VERSION ""

NS_ :

BS_:

BU_: INPUTIOA HPPCTX

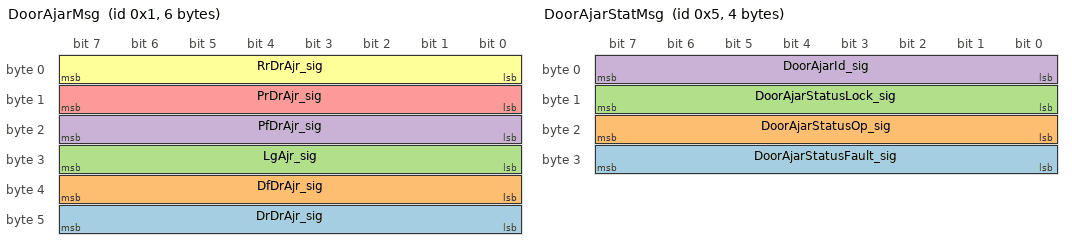
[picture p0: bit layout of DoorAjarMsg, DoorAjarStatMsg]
BO_ 1 DoorAjarMsg: 6 HPPCTX
 SG_ DrDrAjr_sig : 40|8@1+ (1,0) [0|3] "-"  INPUTIOA
 SG_ DfDrAjr_sig : 32|8@1+ (1,0) [0|3] "-"  INPUTIOA
 SG_ LgAjr_sig : 24|8@1+ (1,0) [0|3] "-"  INPUTIOA
 SG_ PfDrAjr_sig : 16|8@1+ (1,0) [0|3] "-"  INPUTIOA
 SG_ PrDrAjr_sig : 8|8@1+ (1,0) [0|3] "-"  INPUTIOA
 SG_ RrDrAjr_sig : 0|8@1+ (1,0) [0|3] "-"  INPUTIOA

BO_ 2 AmbLightMsg: 1 HPPCTX
 SG_ AutLmpSens_sig : 0|8@1+ (1,0) [0|6] "-"  INPUTIOA

BO_ 3 RnLgthMsg: 2 HPPCTX
 SG_ AmbLghtExtLght_sig : 8|8@1+ (1,0) [0|5] "-"  INPUTIOA
 SG_ AmbLghtExtLghtStatCom_sig : 0|8@1+ (1,0) [0|1] "-"  INPUTIOA

BO_ 4 HdLmpSwitchMsg: 1 HPPCTX
 SG_ AbsPos_sig : 0|8@1+ (1,0) [0|5] "-"  INPUTIOA

BO_ 5 DoorAjarStatMsg: 4 INPUTIOA
 SG_ DoorAjarStatusFault_sig : 24|8@1+ (1,0) [0|3] "-"  HPPCTX
 SG_ DoorAjarStatusOp_sig : 16|8@1+ (1,0) [0|3] "-"  HPPCTX
 SG_ DoorAjarStatusLock_sig : 8|8@1+ (1,0) [0|3] "-"  HPPCTX
 SG_ DoorAjarId_sig : 0|8@1+ (1,0) [0|3] "-"  HPPCTX

BO_ 6 AmbLightPDUMsg: 1 INPUTIOA
 SG_ AmbLghtLvlStsPDU_sig : 0|8@1+ (1,0) [0|6] "-"  HPPCTX

BO_ 7 RnLgthPDUMsg: 1 INPUTIOA
 SG_ AmbLghtExtLghtLvl_sig : 0|8@1+ (1,0) [0|6] "-"  HPPCTX

BO_ 8 HdLmpSwitchPDUMsg: 2 INPUTIOA
 SG_ HdLmpSwitchPDUStatus_sig : 0|10@1+ (1,0) [0|6] "-"  HPPCTX

BA_DEF_  "Baudrate" INT 0 1000000;
BA_DEF_  "GenNetworkBaudrate" STRING ;
BA_DEF_  "GenNetworkName" STRING ;
BA_DEF_  "GenNWMApBusSleep" STRING ;
BA_DEF_  "GenNWMApCanNormal" STRING ;
BA_DEF_  "GenNWMApCanOff" STRING ;
BA_DEF_  "GenNWMApCanOn" STRING ;
BA_DEF_  "GenNWMApCanSleep" STRING ;
BA_DEF_  "GenNWMApCanWakeUp" STRING ;
BA_DEF_  "GenNWMGotoMode_Awake" STRING ;
BA_DEF_  "GenNWMGotoMode_BusSleep" STRING ;
BA_DEF_  "GenNWMTalkNM" STRING ;
BA_DEF_ BO_  "NWM-Botschaft" ENUM  "nein","ja";
BA_DEF_ BU_  "NWM-Knoten" ENUM  "nein","ja";
BA_DEF_ BO_  "GenMsgCycleTime" INT 2 50000;
BA_DEF_ BO_  "GenMsgDelayTime" INT 1 1000;
BA_DEF_ BO_  "GenMsgNrOfRepetitions" INT 1 999999;
BA_DEF_ BO_  "GenMsgSendType" ENUM  "cyclic","spontaneous","cyclicIfActive","spontaneousWithDelay","cyclicAndSpontaneous","cyclicAndSpontaneousWithDelay","spontaneousWithRepetition","cyclicIfActiveAndSpontaneousWD";
BA_DEF_  "GenEnvVarEndingDsp" STRING ;
BA_DEF_  "GenEnvVarEndingSnd" STRING ;
BA_DEF_  "GenEnvVarPrefix" STRING ;
BA_DEF_ SG_  "GenSigEnvVarType" ENUM  "int","float","undef";
BA_DEF_DEF_  "GenNetworkBaudrate" "";
BA_DEF_DEF_  "Baudrate" 500000;
BA_DEF_DEF_  "GenNetworkName" "";
BA_DEF_DEF_  "GenNWMApBusSleep" "apBusSleep()";
BA_DEF_DEF_  "GenNWMApCanNormal" "apCanNormal()";
BA_DEF_DEF_  "GenNWMApCanOff" "apCanOff()";
BA_DEF_DEF_  "GenNWMApCanOn" "apCanOn()";
BA_DEF_DEF_  "GenNWMApCanSleep" "apCanSleep()";
BA_DEF_DEF_  "GenNWMApCanWakeUp" "apCanWakeUp()";
BA_DEF_DEF_  "GenNWMGotoMode_Awake" "GotoMode_Awake()";
BA_DEF_DEF_  "GenNWMGotoMode_BusSleep" "GotoMode_BusSleep()";
BA_DEF_DEF_  "GenNWMTalkNM" "TalkNM()";
BA_DEF_DEF_  "NWM-Botschaft" "nein";
BA_DEF_DEF_  "NWM-Knoten" "nein";
BA_DEF_DEF_  "GenMsgCycleTime" 100;
BA_DEF_DEF_  "GenMsgDelayTime" 1;
BA_DEF_DEF_  "GenMsgNrOfRepetitions" 1;
BA_DEF_DEF_  "GenMsgSendType" "spontaneous";
BA_DEF_DEF_  "GenEnvVarEndingDsp" "Dsp_";
BA_DEF_DEF_  "GenEnvVarEndingSnd" "_";
BA_DEF_DEF_  "GenEnvVarPrefix" "Env";
BA_DEF_DEF_  "GenSigEnvVarType" "undef";
BA_ "GenNetworkName" "Network01";
BA_ "GenNetworkBaudrate" "500000";
BA_ "GenMsgSendType" BO_ 5 0;
BA_ "GenMsgSendType" BO_ 6 0;
BA_ "GenMsgSendType" BO_ 7 0;
BA_ "GenMsgSendType" BO_ 8 0;
